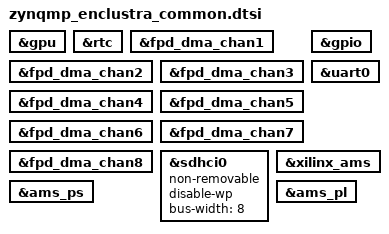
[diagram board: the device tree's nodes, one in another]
&gpu {
	status = "okay";
};

&rtc {
	status = "okay";
};

&fpd_dma_chan1 {
	status = "okay";
};

&fpd_dma_chan2 {
	status = "okay";
};

&fpd_dma_chan3 {
	status = "okay";
};

&fpd_dma_chan4 {
	status = "okay";
};

&fpd_dma_chan5 {
	status = "okay";
};

&fpd_dma_chan6 {
	status = "okay";
};

&fpd_dma_chan7 {
	status = "okay";
};

&fpd_dma_chan8 {
	status = "okay";
};

&gpio {
	status = "okay";
};

&sdhci0 {
	status = "okay";
	non-removable;
	disable-wp;
	bus-width = <8>;
};

&uart0 {
	status = "okay";
};

&xilinx_ams {
	status = "okay";
};

&ams_ps {
	status = "okay";
};

&ams_pl {
	status = "okay";
};
